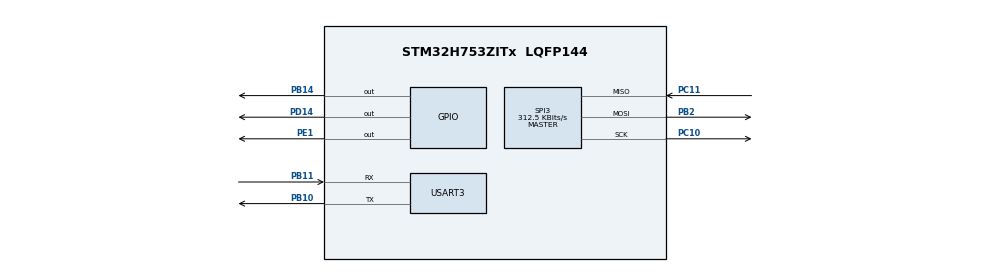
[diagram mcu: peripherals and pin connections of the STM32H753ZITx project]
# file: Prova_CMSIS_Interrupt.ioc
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CORTEX_M7.default_mode_Activation=1
FREERTOS.BinarySemaphores01=BinSem,Dynamic,NULL,Available
FREERTOS.Tasks01=defaultTask,-3,128,StartDefaultTask,Default,NULL,Dynamic,NULL,NULL;Task_Misure,2,128,StartMisure,Default,NULL,Dynamic,NULL,NULL;Task_Comm,0,128,StartComm,Default,NULL,Dynamic,NULL,NULL
FREERTOS.configUSE_NEWLIB_REENTRANT=1
Mcu.Family=STM32H7
Mcu.Name=STM32H753ZITx
Mcu.Package=LQFP144
NVIC.PriorityGroup=NVIC_PRIORITYGROUP_4
NVIC.SPI3_IRQn=true\:5\:0\:false\:false\:true\:true\:true\:true\:true
NVIC.TIM1_UP_IRQn=true\:5\:0\:true\:false\:true\:false\:false\:true\:true
NVIC.TimeBase=TIM1_UP_IRQn
NVIC.TimeBaseIP=TIM1
NVIC.USART3_IRQn=true\:5\:0\:true\:false\:true\:true\:true\:true\:true
PB10.Mode=Asynchronous
PB10.Signal=USART3_TX
PB11.Mode=Asynchronous
PB11.Signal=USART3_RX
PB14.Signal=GPIO_Output
PB2.Mode=Full_Duplex_Master
PB2.Signal=SPI3_MOSI
PC10.Mode=Full_Duplex_Master
PC10.Signal=SPI3_SCK
PC11.Mode=Full_Duplex_Master
PC11.Signal=SPI3_MISO
PD14.PinState=GPIO_PIN_SET
PD14.Signal=GPIO_Output
PE1.Signal=GPIO_Output
PH0-OSC_IN\ (PH0).Mode=HSE-External-Oscillator
PH0-OSC_IN\ (PH0).Signal=RCC_OSC_IN
PH1-OSC_OUT\ (PH1).Mode=HSE-External-Oscillator
PH1-OSC_OUT\ (PH1).Signal=RCC_OSC_OUT
ProjectManager.HeapSize=0x200
ProjectManager.StackSize=0x400
ProjectManager.TargetToolchain=STM32CubeIDE
RCC.ADCFreq_Value=10000000
RCC.APB1Freq_Value=100000000
RCC.APB2Freq_Value=100000000
RCC.APB3Freq_Value=100000000
RCC.APB4Freq_Value=100000000
RCC.CortexFreq_Value=400000000
RCC.D1PPRE=RCC_APB3_DIV2
RCC.D2PPRE1=RCC_APB1_DIV2
RCC.D2PPRE2=RCC_APB2_DIV2
RCC.D3PPRE=RCC_APB4_DIV2
RCC.DIVM1=1
RCC.DIVM2=1
RCC.DIVN1=100
RCC.DIVN2=18
RCC.DIVP2=15
RCC.DIVQ1=15
RCC.HCLKFreq_Value=200000000
RCC.HPRE=RCC_HCLK_DIV2
RCC.HSE_VALUE=8000000
RCC.PLL2FRACN=6144
RCC.PLL3FRACN=0
RCC.PLLFRACN=0
RCC.PLLSourceVirtual=RCC_PLLSOURCE_HSE
RCC.SPI123CLockSelection=RCC_SPI123CLKSOURCE_PLL2
RCC.SYSCLKFreq_VALUE=400000000
RCC.SYSCLKSource=RCC_SYSCLKSOURCE_PLLCLK
RCC.USBFreq_Value=53333333.333333336
SPI3.BaudRatePrescaler=SPI_BAUDRATEPRESCALER_32
SPI3.CalculateBaudRate=312.5 KBits/s
SPI3.DataSize=SPI_DATASIZE_8BIT
SPI3.Direction=SPI_DIRECTION_2LINES
SPI3.Mode=SPI_MODE_MASTER
SPI3.VirtualType=VM_MASTER
USART3.VirtualMode-Asynchronous=VM_ASYNC
VP_FREERTOS_VS_CMSIS_V1.Mode=CMSIS_V1
VP_MEMORYMAP_VS_MEMORYMAP.Mode=CurAppReg
VP_SYS_VS_tim1.Mode=TIM1
board=custom

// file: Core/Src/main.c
/* USER CODE BEGIN Header */
/**
  ******************************************************************************
  * @file           : main.c
  * @brief          : Main program body
  ******************************************************************************
  * @attention
  *
  * Copyright (c) 2025 STMicroelectronics.
  * All rights reserved.
  *
  * This software is licensed under terms that can be found in the LICENSE file
  * in the root directory of this software component.
  * If no LICENSE file comes with this software, it is provided AS-IS.
  *
  ******************************************************************************
  */
/* USER CODE END Header */
#include "main.h"
#include "cmsis_os.h"

/* USER CODE BEGIN Includes */
#include "stdio.h"
#include "stdlib.h"
/* USER CODE END Includes */

SPI_HandleTypeDef hspi3;

UART_HandleTypeDef huart3;

osThreadId defaultTaskHandle;
osThreadId Task_MisureHandle;
osThreadId Task_CommHandle;
osSemaphoreId BinSemHandle;
/* USER CODE BEGIN PV */
int flag=0;
/* USER CODE END PV */

void SystemClock_Config(void);
static void MPU_Config(void);
static void MX_GPIO_Init(void);
static void MX_SPI3_Init(void);
static void MX_USART3_UART_Init(void);
void StartDefaultTask(void const * argument);
void StartMisure(void const * argument);
void StartComm(void const * argument);

/* USER CODE BEGIN PFP */
void User_UartCompleteCallback(UART_HandleTypeDef *huart);
/* USER CODE END PFP */

int main(void)
{

  /* MPU Configuration--------------------------------------------------------*/
  MPU_Config();

  /* MCU Configuration--------------------------------------------------------*/

  /* Reset of all peripherals, Initializes the Flash interface and the Systick. */
  HAL_Init();

  /* Configure the system clock */
  SystemClock_Config();

  /* Initialize all configured peripherals */
  MX_GPIO_Init();
  MX_SPI3_Init();
  MX_USART3_UART_Init();
  /* USER CODE BEGIN 2 */
  HAL_UART_RegisterCallback(&huart3, HAL_UART_TX_COMPLETE_CB_ID, User_UartCompleteCallback);
  /* USER CODE END 2 */

  /* Create the semaphores(s) */
  /* definition and creation of BinSem */
  osSemaphoreDef(BinSem);
  BinSemHandle = osSemaphoreCreate(osSemaphore(BinSem), 1);

  /* Create the thread(s) */
  /* definition and creation of defaultTask */
  osThreadDef(defaultTask, StartDefaultTask, osPriorityIdle, 0, 128);
  defaultTaskHandle = osThreadCreate(osThread(defaultTask), NULL);

  /* definition and creation of Task_Misure */
  osThreadDef(Task_Misure, StartMisure, osPriorityHigh, 0, 128);
  Task_MisureHandle = osThreadCreate(osThread(Task_Misure), NULL);

  /* definition and creation of Task_Comm */
  osThreadDef(Task_Comm, StartComm, osPriorityNormal, 0, 128);
  Task_CommHandle = osThreadCreate(osThread(Task_Comm), NULL);

  /* Start scheduler */
  osKernelStart();

  /* We should never get here as control is now taken by the scheduler */

  /* Infinite loop */
  while (1)
  {

  }
}

void SystemClock_Config(void)
{
  RCC_OscInitTypeDef RCC_OscInitStruct = {0};
  RCC_ClkInitTypeDef RCC_ClkInitStruct = {0};

  /** Supply configuration update enable
  */
  HAL_PWREx_ConfigSupply(PWR_LDO_SUPPLY);

  /** Configure the main internal regulator output voltage
  */
  __HAL_PWR_VOLTAGESCALING_CONFIG(PWR_REGULATOR_VOLTAGE_SCALE1);

  while(!__HAL_PWR_GET_FLAG(PWR_FLAG_VOSRDY)) {}

  /** Initializes the RCC Oscillators according to the specified parameters
  * in the RCC_OscInitTypeDef structure.
  */
  RCC_OscInitStruct.OscillatorType = RCC_OSCILLATORTYPE_HSE;
  RCC_OscInitStruct.HSEState = RCC_HSE_ON;
  RCC_OscInitStruct.PLL.PLLState = RCC_PLL_ON;
  RCC_OscInitStruct.PLL.PLLSource = RCC_PLLSOURCE_HSE;
  RCC_OscInitStruct.PLL.PLLM = 1;
  RCC_OscInitStruct.PLL.PLLN = 100;
  RCC_OscInitStruct.PLL.PLLP = 2;
  RCC_OscInitStruct.PLL.PLLQ = 15;
  RCC_OscInitStruct.PLL.PLLR = 2;
  RCC_OscInitStruct.PLL.PLLRGE = RCC_PLL1VCIRANGE_3;
  RCC_OscInitStruct.PLL.PLLVCOSEL = RCC_PLL1VCOWIDE;
  RCC_OscInitStruct.PLL.PLLFRACN = 0;
  if (HAL_RCC_OscConfig(&RCC_OscInitStruct) != HAL_OK)
  {
    Error_Handler();
  }

  /** Initializes the CPU, AHB and APB buses clocks
  */
  RCC_ClkInitStruct.ClockType = RCC_CLOCKTYPE_HCLK|RCC_CLOCKTYPE_SYSCLK
                              |RCC_CLOCKTYPE_PCLK1|RCC_CLOCKTYPE_PCLK2
                              |RCC_CLOCKTYPE_D3PCLK1|RCC_CLOCKTYPE_D1PCLK1;
  RCC_ClkInitStruct.SYSCLKSource = RCC_SYSCLKSOURCE_PLLCLK;
  RCC_ClkInitStruct.SYSCLKDivider = RCC_SYSCLK_DIV1;
  RCC_ClkInitStruct.AHBCLKDivider = RCC_HCLK_DIV2;
  RCC_ClkInitStruct.APB3CLKDivider = RCC_APB3_DIV2;
  RCC_ClkInitStruct.APB1CLKDivider = RCC_APB1_DIV2;
  RCC_ClkInitStruct.APB2CLKDivider = RCC_APB2_DIV2;
  RCC_ClkInitStruct.APB4CLKDivider = RCC_APB4_DIV2;

  if (HAL_RCC_ClockConfig(&RCC_ClkInitStruct, FLASH_LATENCY_2) != HAL_OK)
  {
    Error_Handler();
  }
}

static void MX_SPI3_Init(void)
{

  /* SPI3 parameter configuration*/
  hspi3.Instance = SPI3;
  hspi3.Init.Mode = SPI_MODE_MASTER;
  hspi3.Init.Direction = SPI_DIRECTION_2LINES;
  hspi3.Init.DataSize = SPI_DATASIZE_8BIT;
  hspi3.Init.CLKPolarity = SPI_POLARITY_LOW;
  hspi3.Init.CLKPhase = SPI_PHASE_1EDGE;
  hspi3.Init.NSS = SPI_NSS_SOFT;
  hspi3.Init.BaudRatePrescaler = SPI_BAUDRATEPRESCALER_32;
  hspi3.Init.FirstBit = SPI_FIRSTBIT_MSB;
  hspi3.Init.TIMode = SPI_TIMODE_DISABLE;
  hspi3.Init.CRCCalculation = SPI_CRCCALCULATION_DISABLE;
  hspi3.Init.CRCPolynomial = 0x0;
  hspi3.Init.NSSPMode = SPI_NSS_PULSE_ENABLE;
  hspi3.Init.NSSPolarity = SPI_NSS_POLARITY_LOW;
  hspi3.Init.FifoThreshold = SPI_FIFO_THRESHOLD_01DATA;
  hspi3.Init.TxCRCInitializationPattern = SPI_CRC_INITIALIZATION_ALL_ZERO_PATTERN;
  hspi3.Init.RxCRCInitializationPattern = SPI_CRC_INITIALIZATION_ALL_ZERO_PATTERN;
  hspi3.Init.MasterSSIdleness = SPI_MASTER_SS_IDLENESS_00CYCLE;
  hspi3.Init.MasterInterDataIdleness = SPI_MASTER_INTERDATA_IDLENESS_00CYCLE;
  hspi3.Init.MasterReceiverAutoSusp = SPI_MASTER_RX_AUTOSUSP_DISABLE;
  hspi3.Init.MasterKeepIOState = SPI_MASTER_KEEP_IO_STATE_DISABLE;
  hspi3.Init.IOSwap = SPI_IO_SWAP_DISABLE;
  if (HAL_SPI_Init(&hspi3) != HAL_OK)
  {
    Error_Handler();
  }

}

static void MX_USART3_UART_Init(void)
{

  huart3.Instance = USART3;
  huart3.Init.BaudRate = 115200;
  huart3.Init.WordLength = UART_WORDLENGTH_8B;
  huart3.Init.StopBits = UART_STOPBITS_1;
  huart3.Init.Parity = UART_PARITY_NONE;
  huart3.Init.Mode = UART_MODE_TX_RX;
  huart3.Init.HwFlowCtl = UART_HWCONTROL_NONE;
  huart3.Init.OverSampling = UART_OVERSAMPLING_16;
  huart3.Init.OneBitSampling = UART_ONE_BIT_SAMPLE_DISABLE;
  huart3.Init.ClockPrescaler = UART_PRESCALER_DIV1;
  huart3.AdvancedInit.AdvFeatureInit = UART_ADVFEATURE_NO_INIT;
  if (HAL_UART_Init(&huart3) != HAL_OK)
  {
    Error_Handler();
  }
  if (HAL_UARTEx_SetTxFifoThreshold(&huart3, UART_TXFIFO_THRESHOLD_1_8) != HAL_OK)
  {
    Error_Handler();
  }
  if (HAL_UARTEx_SetRxFifoThreshold(&huart3, UART_RXFIFO_THRESHOLD_1_8) != HAL_OK)
  {
    Error_Handler();
  }
  if (HAL_UARTEx_DisableFifoMode(&huart3) != HAL_OK)
  {
    Error_Handler();
  }

}

static void MX_GPIO_Init(void)
{
  GPIO_InitTypeDef GPIO_InitStruct = {0};

  /* GPIO Ports Clock Enable */
  __HAL_RCC_GPIOH_CLK_ENABLE();
  __HAL_RCC_GPIOB_CLK_ENABLE();
  __HAL_RCC_GPIOD_CLK_ENABLE();
  __HAL_RCC_GPIOC_CLK_ENABLE();
  __HAL_RCC_GPIOE_CLK_ENABLE();

  /*Configure GPIO pin Output Level */
  HAL_GPIO_WritePin(GPIOB, GPIO_PIN_14, GPIO_PIN_RESET);

  /*Configure GPIO pin Output Level */
  HAL_GPIO_WritePin(GPIOD, GPIO_PIN_14, GPIO_PIN_SET);

  /*Configure GPIO pin Output Level */
  HAL_GPIO_WritePin(GPIOE, GPIO_PIN_1, GPIO_PIN_RESET);

  /*Configure GPIO pin : PB14 */
  GPIO_InitStruct.Pin = GPIO_PIN_14;
  GPIO_InitStruct.Mode = GPIO_MODE_OUTPUT_PP;
  GPIO_InitStruct.Pull = GPIO_NOPULL;
  GPIO_InitStruct.Speed = GPIO_SPEED_FREQ_LOW;
  HAL_GPIO_Init(GPIOB, &GPIO_InitStruct);

  /*Configure GPIO pin : PD14 */
  GPIO_InitStruct.Pin = GPIO_PIN_14;
  GPIO_InitStruct.Mode = GPIO_MODE_OUTPUT_PP;
  GPIO_InitStruct.Pull = GPIO_NOPULL;
  GPIO_InitStruct.Speed = GPIO_SPEED_FREQ_LOW;
  HAL_GPIO_Init(GPIOD, &GPIO_InitStruct);

  /*Configure GPIO pin : PE1 */
  GPIO_InitStruct.Pin = GPIO_PIN_1;
  GPIO_InitStruct.Mode = GPIO_MODE_OUTPUT_PP;
  GPIO_InitStruct.Pull = GPIO_NOPULL;
  GPIO_InitStruct.Speed = GPIO_SPEED_FREQ_LOW;
  HAL_GPIO_Init(GPIOE, &GPIO_InitStruct);

}

/* USER CODE BEGIN 4 */
void User_UartCompleteCallback(UART_HandleTypeDef *huart)
{
      HAL_GPIO_TogglePin(GPIOB, GPIO_PIN_14);
      osSemaphoreRelease(BinSemHandle);
}
/* USER CODE END 4 */

void StartDefaultTask(void const * argument)
{
  for(;;)
  {
    osDelay(1);
  }
}

void StartMisure(void const * argument)
{
  /* USER CODE BEGIN StartMisure */
  /* Infinite loop */
  for(;;)
  {
	  flag=0;
      char buffer[32];
      int length = sprintf(buffer, "Scrittura uart\r\n");
       // Invia via UART
      HAL_UART_Transmit_IT(&huart3, (uint8_t*)buffer, length);
      osSemaphoreWait(BinSemHandle, osWaitForever);
  }
  /* USER CODE END StartMisure */
}

void StartComm(void const * argument)
{
  /* USER CODE BEGIN StartComm */
  /* Infinite loop */
  for(;;)
  {
    HAL_GPIO_TogglePin(GPIOE, GPIO_PIN_1);
  }
  /* USER CODE END StartComm */
}

 /* MPU Configuration */

void MPU_Config(void)
{
  MPU_Region_InitTypeDef MPU_InitStruct = {0};

  /* Disables the MPU */
  HAL_MPU_Disable();

  /** Initializes and configures the Region and the memory to be protected
  */
  MPU_InitStruct.Enable = MPU_REGION_ENABLE;
  MPU_InitStruct.Number = MPU_REGION_NUMBER0;
  MPU_InitStruct.BaseAddress = 0x0;
  MPU_InitStruct.Size = MPU_REGION_SIZE_4GB;
  MPU_InitStruct.SubRegionDisable = 0x87;
  MPU_InitStruct.TypeExtField = MPU_TEX_LEVEL0;
  MPU_InitStruct.AccessPermission = MPU_REGION_NO_ACCESS;
  MPU_InitStruct.DisableExec = MPU_INSTRUCTION_ACCESS_DISABLE;
  MPU_InitStruct.IsShareable = MPU_ACCESS_SHAREABLE;
  MPU_InitStruct.IsCacheable = MPU_ACCESS_NOT_CACHEABLE;
  MPU_InitStruct.IsBufferable = MPU_ACCESS_NOT_BUFFERABLE;

  HAL_MPU_ConfigRegion(&MPU_InitStruct);
  /* Enables the MPU */
  HAL_MPU_Enable(MPU_PRIVILEGED_DEFAULT);

}

void HAL_TIM_PeriodElapsedCallback(TIM_HandleTypeDef *htim)
{
  if (htim->Instance == TIM1)
  {
    HAL_IncTick();
  }
}

void Error_Handler(void)
{
  __disable_irq();
  while (1)
  {
  }
}
